# STM32MP157 register map
File version: 1.6
CPU: CM4 r0p1, little endian, no MPU, FPU, 4 interrupt priority bits
Registers are 32-bit, read-write, reset 0x0 unless marked. A register's access mark holds for its fields unless they carry their own. Offsets are from the block's base; [hi:lo] are bit positions; {n}, {i} and the like mark numbered series.

## DDRPHYC
Base 0x5A004000
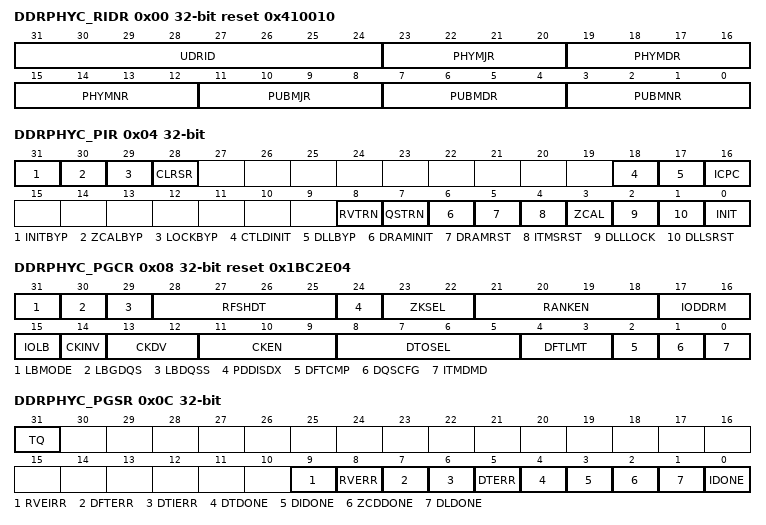
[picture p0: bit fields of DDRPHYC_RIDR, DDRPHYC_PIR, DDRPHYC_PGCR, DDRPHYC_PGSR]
0x00 DDRPHYC_RIDR ro reset 0x410010 — DDRPHYC revision ID register
  [31:24] UDRID, [23:20] PHYMJR, [19:16] PHYMDR, [15:12] PHYMNR, [11:8] PUBMJR, [7:4] PUBMDR, [3:0] PUBMNR
0x04 DDRPHYC_PIR wo — DDRPHYC PHY initialization register
  [31] INITBYP, [30] ZCALBYP, [29] LOCKBYP, [28] CLRSR, [18] CTLDINIT, [17] DLLBYP, [16] ICPC, [8] RVTRN, [7] QSTRN, [6] DRAMINIT, [5] DRAMRST, [4] ITMSRST, [3] ZCAL, [2] DLLLOCK, [1] DLLSRST, [0] INIT
0x08 DDRPHYC_PGCR reset 0x1BC2E04 — DDRPHYC PHY global control register
  [31] LBMODE, [30] LBGDQS, [29] LBDQSS, [28:25] RFSHDT, [24] PDDISDX, [23:22] ZKSEL, [21:18] RANKEN, [17:16] IODDRM, [15] IOLB, [14] CKINV, [13:12] CKDV, [11:9] CKEN, [8:5] DTOSEL, [4:3] DFTLMT, [2] DFTCMP, [1] DQSCFG, [0] ITMDMD
0x0C DDRPHYC_PGSR ro — DDRPHYC PHY global status register
  [31] TQ, [9] RVEIRR, [8] RVERR, [7] DFTERR, [6] DTIERR, [5] DTERR, [4] DTDONE, [3] DIDONE, [2] ZCDDONE, [1] DLDONE, [0] IDONE
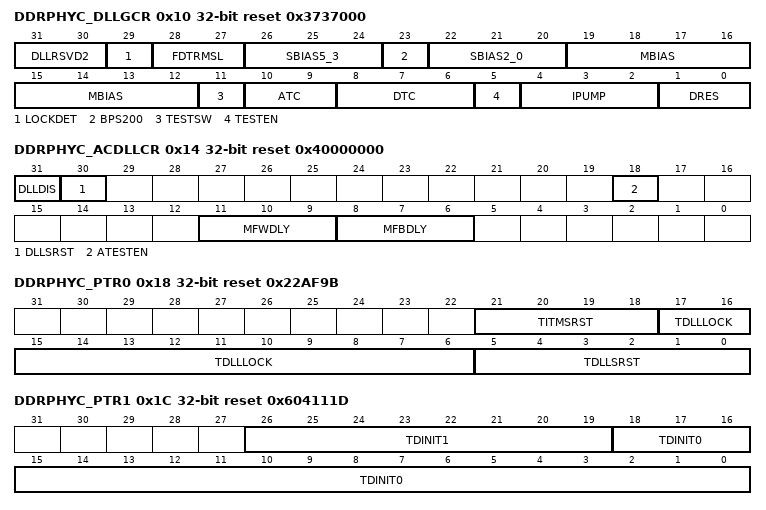
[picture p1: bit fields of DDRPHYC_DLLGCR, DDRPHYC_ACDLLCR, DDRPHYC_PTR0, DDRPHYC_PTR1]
0x10 DDRPHYC_DLLGCR reset 0x3737000 — DDRPHYC DDR global control register
  [31:30] DLLRSVD2, [29] LOCKDET, [28:27] FDTRMSL, [26:24] SBIAS5_3, [23] BPS200, [22:20] SBIAS2_0, [19:12] MBIAS, [11] TESTSW, [10:9] ATC, [8:6] DTC, [5] TESTEN, [4:2] IPUMP, [1:0] DRES
0x14 DDRPHYC_ACDLLCR reset 0x40000000 — DDRPHYC AC DLL control register
  [31] DLLDIS, [30] DLLSRST, [18] ATESTEN, [11:9] MFWDLY, [8:6] MFBDLY
0x18 DDRPHYC_PTR0 reset 0x22AF9B — DDRPHYC PT register 0
  [21:18] TITMSRST, [17:6] TDLLLOCK, [5:0] TDLLSRST
0x1C DDRPHYC_PTR1 reset 0x604111D — DDRPHYC PT register 1
  [26:19] TDINIT1, [18:0] TDINIT0
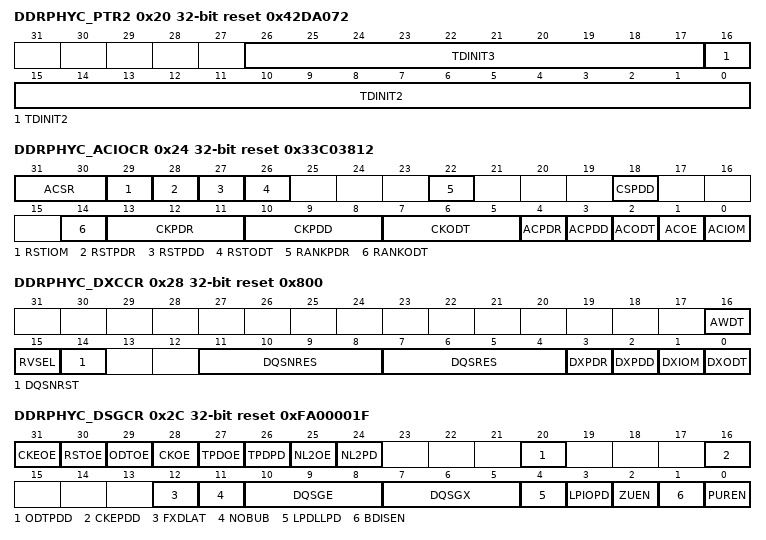
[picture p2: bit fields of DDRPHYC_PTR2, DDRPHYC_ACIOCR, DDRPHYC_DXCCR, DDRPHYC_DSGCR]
0x20 DDRPHYC_PTR2 reset 0x42DA072 — DDRPHYC PT register 2
  [26:17] TDINIT3, [16:0] TDINIT2
0x24 DDRPHYC_ACIOCR reset 0x33C03812 — DDRPHYC ACIOC register
  [31:30] ACSR, [29] RSTIOM, [28] RSTPDR, [27] RSTPDD, [26] RSTODT, [22] RANKPDR, [18] CSPDD, [14] RANKODT, [13:11] CKPDR, [10:8] CKPDD, [7:5] CKODT, [4] ACPDR, [3] ACPDD, [2] ACODT, [1] ACOE, [0] ACIOM
0x28 DDRPHYC_DXCCR reset 0x800 — DDRPHYC DXCC register
  [16] AWDT, [15] RVSEL, [14] DQSNRST, [11:8] DQSNRES, [7:4] DQSRES, [3] DXPDR, [2] DXPDD, [1] DXIOM, [0] DXODT
0x2C DDRPHYC_DSGCR reset 0xFA00001F — DDRPHYC DSGC register
  [31] CKEOE, [30] RSTOE, [29] ODTOE, [28] CKOE, [27] TPDOE, [26] TPDPD, [25] NL2OE, [24] NL2PD, [20] ODTPDD, [16] CKEPDD, [12] FXDLAT, [11] NOBUB, [10:8] DQSGE, [7:5] DQSGX, [4] LPDLLPD, [3] LPIOPD, [2] ZUEN, [1] BDISEN, [0] PUREN
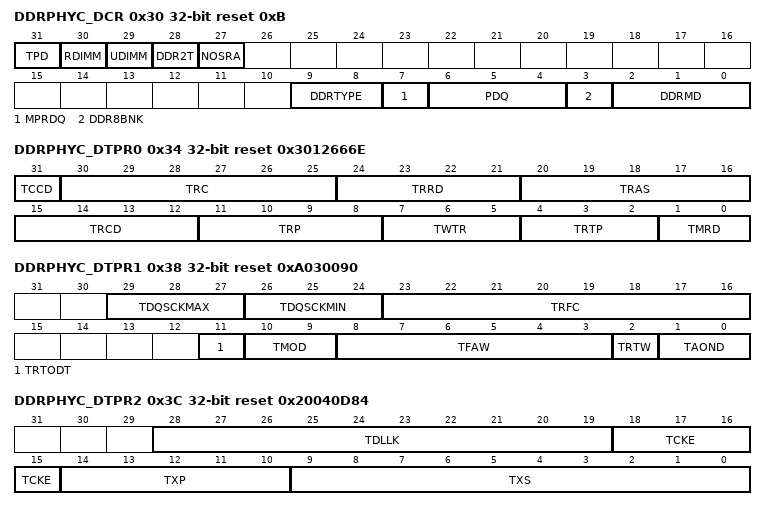
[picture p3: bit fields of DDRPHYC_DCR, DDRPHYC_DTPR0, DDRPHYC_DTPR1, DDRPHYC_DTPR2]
0x30 DDRPHYC_DCR reset 0xB — DDRPHYC DC register
  [31] TPD, [30] RDIMM, [29] UDIMM, [28] DDR2T, [27] NOSRA, [9:8] DDRTYPE, [7] MPRDQ, [6:4] PDQ, [3] DDR8BNK, [2:0] DDRMD
0x34 DDRPHYC_DTPR0 reset 0x3012666E — DDRPHYC DTP register 0
  [31] TCCD, [30:25] TRC, [24:21] TRRD, [20:16] TRAS, [15:12] TRCD, [11:8] TRP, [7:5] TWTR, [4:2] TRTP, [1:0] TMRD
0x38 DDRPHYC_DTPR1 reset 0xA030090 — DDRPHYC DTP register 1
  [29:27] TDQSCKMAX, [26:24] TDQSCKMIN, [23:16] TRFC, [11] TRTODT, [10:9] TMOD, [8:3] TFAW, [2] TRTW, [1:0] TAOND
0x3C DDRPHYC_DTPR2 reset 0x20040D84 — DDRPHYC DTP register 2
  [28:19] TDLLK, [18:15] TCKE, [14:10] TXP, [9:0] TXS
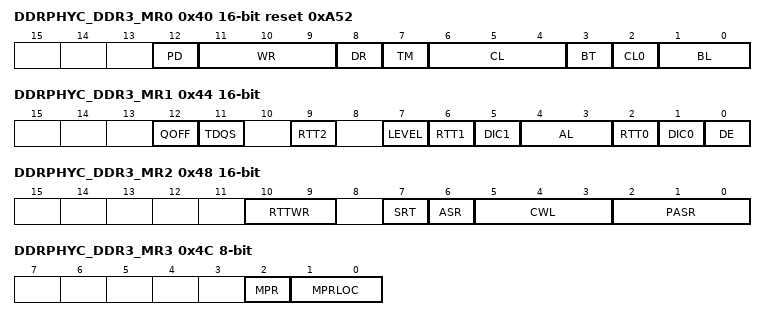
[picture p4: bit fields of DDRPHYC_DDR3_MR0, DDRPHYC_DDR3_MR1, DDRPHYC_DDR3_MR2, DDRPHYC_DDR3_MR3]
0x40 DDRPHYC_DDR3_MR0 16-bit reset 0xA52 — DDRPHYC MR0 register for DDR3
  [12] PD, [11:9] WR, [8] DR, [7] TM, [6:4] CL, [3] BT, [2] CL0, [1:0] BL
0x44 DDRPHYC_DDR3_MR1 16-bit — DDRPHYC MR1 register for DDR3
  [12] QOFF, [11] TDQS, [9] RTT2, [7] LEVEL, [6] RTT1, [5] DIC1, [4:3] AL, [2] RTT0, [1] DIC0, [0] DE
0x48 DDRPHYC_DDR3_MR2 16-bit — DDRPHYC MR2 register for DDR3
  [10:9] RTTWR, [7] SRT, [6] ASR, [5:3] CWL, [2:0] PASR
0x4C DDRPHYC_DDR3_MR3 8-bit — DDRPHYC MR3 register for DDR3
  [2] MPR, [1:0] MPRLOC
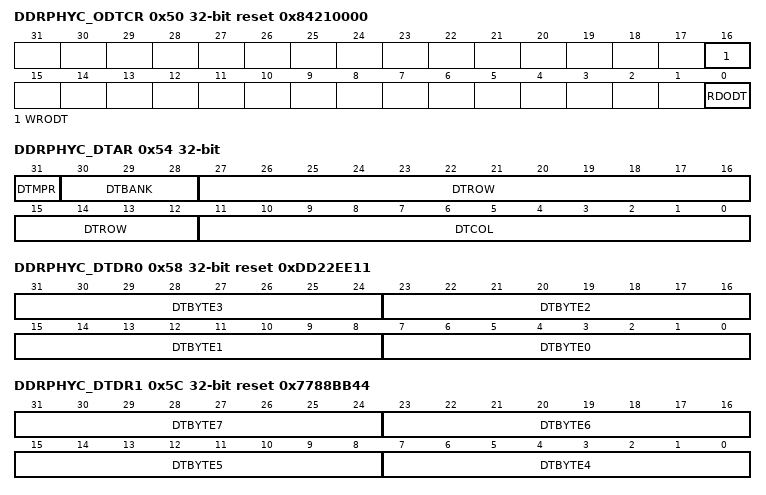
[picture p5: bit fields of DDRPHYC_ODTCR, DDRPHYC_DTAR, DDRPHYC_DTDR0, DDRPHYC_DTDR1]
0x50 DDRPHYC_ODTCR reset 0x84210000 — DDRPHYC ODTC register
  [16] WRODT, [0] RDODT
0x54 DDRPHYC_DTAR — DDRPHYC DTA register
  [31] DTMPR, [30:28] DTBANK, [27:12] DTROW, [11:0] DTCOL
0x58 DDRPHYC_DTDR0 reset 0xDD22EE11 — DDRPHYC DTD register 0
  [8n+7:8n] DTBYTE{n} (n=0..3)
0x5C DDRPHYC_DTDR1 reset 0x7788BB44 — DDRPHYC DTD register 1
  [8n-25:8n-32] DTBYTE{n} (n=4..7)
0x178 DDRPHYC_GPR0 — DDRPHYC general purpose register 0
0x17C DDRPHYC_GPR1 — DDRPHYC general purpose register 1
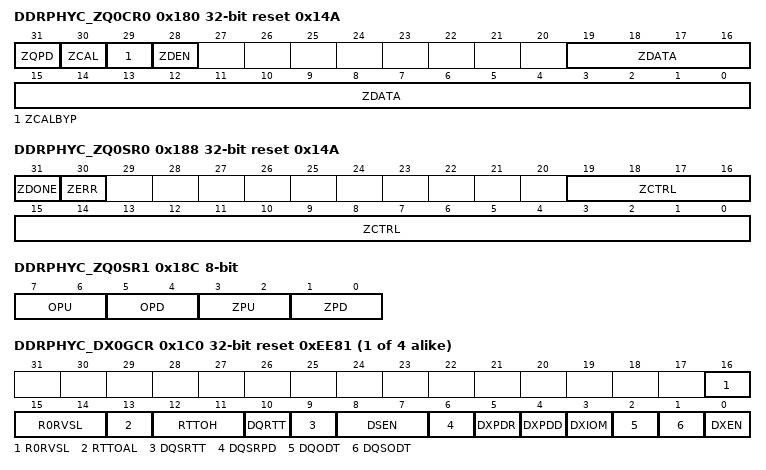
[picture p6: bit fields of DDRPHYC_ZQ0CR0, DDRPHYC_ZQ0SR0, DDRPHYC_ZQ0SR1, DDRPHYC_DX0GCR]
0x180 DDRPHYC_ZQ0CR0 reset 0x14A — DDRPHYC ZQ0C register 0
  [31] ZQPD, [30] ZCAL, [29] ZCALBYP, [28] ZDEN, [19:0] ZDATA
0x184 DDRPHYC_ZQ0CR1 8-bit reset 0x7B
  [7:0] ZPROG
0x188 DDRPHYC_ZQ0SR0 ro reset 0x14A — DDRPHYC ZQ0S register 0
  [31] ZDONE, [30] ZERR, [19:0] ZCTRL
0x18C DDRPHYC_ZQ0SR1 8-bit ro — DDRPHYC ZQ0S register 1
  [7:6] OPU, [5:4] OPD, [3:2] ZPU, [1:0] ZPD
{0x1C0+0x40*i} DDRPHYC_DX{i}GCR reset 0xEE81 (i=0..3) — DDRPHYC byte lane {i} GC register
  [16:14] R0RVSL, [13] RTTOAL, [12:11] RTTOH, [10] DQRTT, [9] DQSRTT, [8:7] DSEN, [6] DQSRPD, [5] DXPDR, [4] DXPDD, [3] DXIOM, [2] DQODT, [1] DQSODT, [0] DXEN
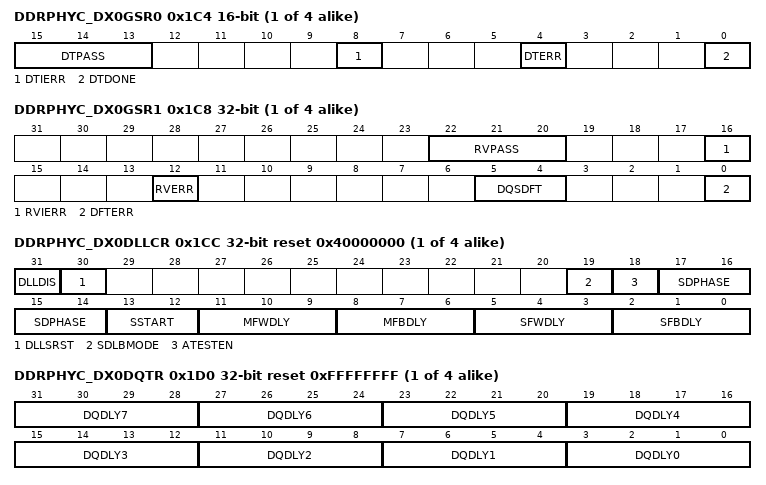
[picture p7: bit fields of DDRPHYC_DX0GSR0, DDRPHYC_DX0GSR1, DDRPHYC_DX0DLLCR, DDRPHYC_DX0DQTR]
{0x1C4+0x40*i} DDRPHYC_DX{i}GSR0 16-bit ro (i=0..3) — DDRPHYC byte lane {i} GS register 0
  [15:13] DTPASS, [8] DTIERR, [4] DTERR, [0] DTDONE
{0x1C8+0x40*i} DDRPHYC_DX{i}GSR1 ro (i=0..3) — DDRPHYC byte lane {i} GS register 1
  [22:20] RVPASS, [16] RVIERR, [12] RVERR, [5:4] DQSDFT, [0] DFTERR
{0x1CC+0x40*i} DDRPHYC_DX{i}DLLCR reset 0x40000000 (i=0..3) — DDRPHYC byte lane {i} DLLC register
  [31] DLLDIS, [30] DLLSRST, [19] SDLBMODE, [18] ATESTEN, [17:14] SDPHASE, [13:12] SSTART, [11:9] MFWDLY, [8:6] MFBDLY, [5:3] SFWDLY, [2:0] SFBDLY
{0x1D0+0x40*i} DDRPHYC_DX{i}DQTR reset 0xFFFFFFFF (i=0..3) — DDRPHYC byte lane {i} DQT register
  [4n+3:4n] DQDLY{n} (n=0..7)
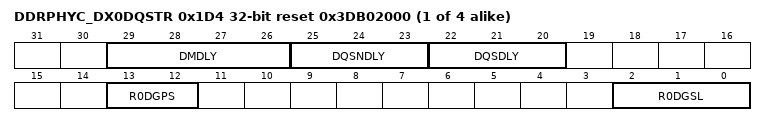
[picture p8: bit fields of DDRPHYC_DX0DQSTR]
{0x1D4+0x40*i} DDRPHYC_DX{i}DQSTR reset 0x3DB02000 (i=0..3) — DDRPHYC byte lane {i} DQST register
  [29:26] DMDLY, [25:23] DQSNDLY, [22:20] DQSDLY, [13:12] R0DGPS, [2:0] R0DGSL
